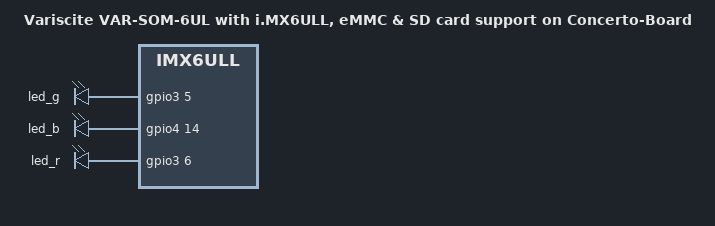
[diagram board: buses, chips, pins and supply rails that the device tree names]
/*
 * Copyright (C) 2019 Variscite Ltd. - https://www.variscite.com
 *
 * This program is free software; you can redistribute it and/or modify
 * it under the terms of the GNU General Public License version 2 as
 * published by the Free Software Foundation.
 */

/dts-v1/;

#include "imx6ull.dtsi"

#include "imx6ull-var-som.dtsi"
#include "imx6ul-imx6ull-var-som-emmc.dtsi"

#include "imx6ull-var-som-concerto-board.dtsi"
#include "imx6ul-imx6ull-var-som-concerto-board-sd-card.dtsi"

/ {
    model = "Variscite VAR-SOM-6UL with i.MX6ULL, eMMC & SD card support on Concerto-Board";
    compatible = "variscite,imx6ul-var-som", "fsl,imx6ull";
    run-control {
        compatible = "gpio-leds";
        pinctrl-names = "default";
        pinctrl-0 = <&pinctrl_java_gpio>, <&pinctrl_java_gpio_snvs>;
        status = "okay";
        led_g {
            gpios = <&gpio3 5 GPIO_ACTIVE_HIGH>;
            default-state = "off";
        };
		led_b {
            gpios = <&gpio4 14 GPIO_ACTIVE_HIGH>;
            default-state = "off";
        };
        led_r {
            gpios = <&gpio3 6 GPIO_ACTIVE_HIGH>;
            default-state = "off";
        };
    };
};

&iomuxc {
    pinctrl_java_gpio: javagpiogrp {
        fsl,pins = <
        MX6UL_PAD_LCD_DATA01__GPIO3_IO06 0x1b0b0
        MX6UL_PAD_LCD_DATA00__GPIO3_IO05 0x1b0b0
        MX6UL_PAD_NAND_CE1_B__GPIO4_IO14 0x1b0b0
        >;
    };
};

/* SVNS pad needs to be configured in iomuxc_snvs */
&iomuxc_snvs {
	pinctrl_java_gpio_snvs: javagpiogrpsnvs {
		fsl,pins = <
		MX6ULL_PAD_SNVS_TAMPER9__GPIO5_IO09 0x1b0b0
		MX6ULL_PAD_SNVS_TAMPER7__GPIO5_IO07 0x1b0b0
		MX6ULL_PAD_SNVS_TAMPER3__GPIO5_IO03 0x1b0b0
		>;
	};
};

/* Disabled to avoid conflicts with GPIO3_IO07, GPIO3_IO09, GPIO3_IO08, GPIO3_IO17, GPIO3_IO25, GPIO3_IO18 */
&lcdif {
    status = "disabled";
};

/* Disabled to avoid conflicts with GPIO1_IO05 */
&pwm4 {
    status = "disabled";
};

/* Disabling this node to avoid conflict with GPIO1_IO04 for GPIO1_IO04 and GPIO1_IO02 pin */
&tsc {
    status = "disabled";
};

